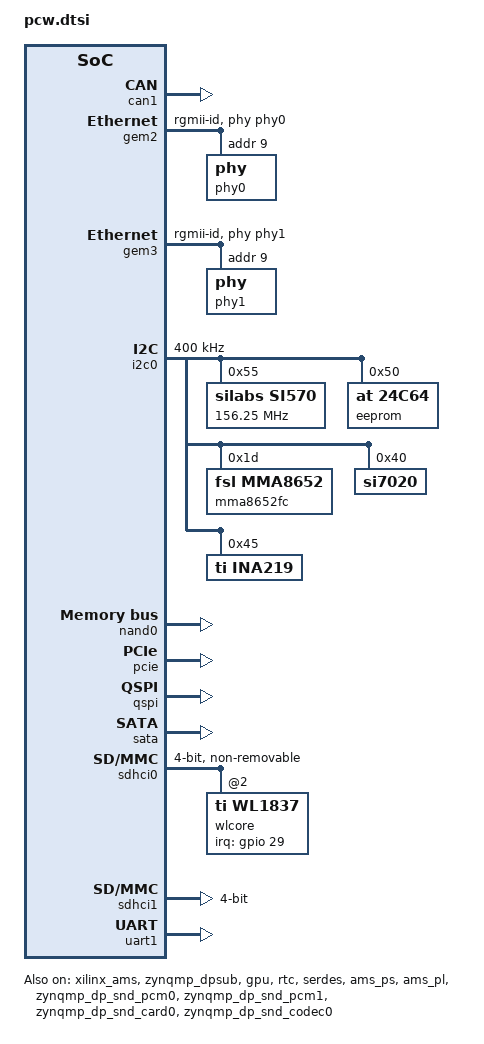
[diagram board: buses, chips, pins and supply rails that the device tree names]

/*
 * CAUTION: This file is automatically generated by Xilinx.
 * Version: XSCT 2018.3
 * Today is: Fri Feb  1 12:27:28 2019
 */


&gic {
	num_cpus = <2>;
	num_interrupts = <96>;
};
&lpd_dma_chan1 {
	status = "okay";
};
&lpd_dma_chan2 {
	status = "okay";
};
&lpd_dma_chan3 {
	status = "okay";
};
&lpd_dma_chan4 {
	status = "okay";
};
&lpd_dma_chan5 {
	status = "okay";
};
&lpd_dma_chan6 {
	status = "okay";
};
&lpd_dma_chan7 {
	status = "okay";
};
&lpd_dma_chan8 {
	status = "okay";
};
&xilinx_ams {
	status = "okay";
};
&perf_monitor_ocm {
	xlnx,enable-32bit-filter-id = <0x1>;
	xlnx,enable-advanced = <0x1>;
	xlnx,enable-event-count = <0x1>;
	xlnx,enable-event-log = <0x0>;
	xlnx,enable-profile = <0x0>;
	xlnx,enable-trace = <0x0>;
	xlnx,fifo-axis-depth = <0x20>;
	xlnx,fifo-axis-tdata-width = <0x38>;
	xlnx,fifo-axis-tid-width = <0x1>;
	xlnx,global-count-width = <0x20>;
	xlnx,have-sampled-metric-cnt = <0x1>;
	xlnx,metric-count-scale = <0x1>;
	xlnx,metrics-sample-count-width = <0x20>;
	xlnx,num-monitor-slots = <0x1>;
	xlnx,num-of-counters = <0x3>;
};
&can1 {
	status = "okay";
};
&zynqmp_dpsub {
	phy-names = "dp-phy0","dp-phy1";
	phys = <&lane3 5 0 2 135000000>,
		<&lane2 5 1 2 135000000>;
	status = "okay";
	xlnx,max-lanes = <2>;
};
&xlnx_dpdma {
	status = "okay";
};
&gem2 {
	status = "okay";
	phy-handle = <&phy0>;
	phy-mode = "rgmii-id";
    xlnx,ptp-enet-clock = <0x0>;
	phy-reset-gpio = <&gpio 10 1>;
	phy-reset-duration = <2>;
	phy-reset-active-low = <1>;
	local-mac-address = [00 0a 35 00 00 00];
	phy0: phy@9 {
			reg = <0x9>;
			ti,rx-internal-delay = <0x8>;
			ti,tx-internal-delay = <0xa>;
			ti,fifo-depth = <0x1>;
		};
};
&gem3 {
	status = "okay";
	phy-handle = <&phy1>;
	phy-mode = "rgmii-id";
	phy-reset-gpio = <&gpio 11 1>;
	phy-reset-duration = <2>;
	phy-reset-active-low = <1>;
	local-mac-address = [00 0a 35 00 00 01];
	phy1: phy@9 {
		reg = <0x9>;
		ti,rx-internal-delay = <0x8>;
		ti,tx-internal-delay = <0xa>;
		ti,fifo-depth = <0x1>;
		ti,rxctrl-strap-worka;
	};
};
&fpd_dma_chan1 {
	status = "okay";
};
&fpd_dma_chan2 {
	status = "okay";
};
&fpd_dma_chan3 {
	status = "okay";
};
&fpd_dma_chan4 {
	status = "okay";
};
&fpd_dma_chan5 {
	status = "okay";
};
&fpd_dma_chan6 {
	status = "okay";
};
&fpd_dma_chan7 {
	status = "okay";
};
&fpd_dma_chan8 {
	status = "okay";
};
&gpio {
	emio-gpio-width = <32>;
	gpio-mask-high = <0x0>;
	gpio-mask-low = <0x5600>;
	status = "okay";
};
&gpu {
	status = "okay";
};
&i2c0 {
	clock-frequency = <400000>;
	status = "okay";
	si570: clock-generator@55 {
		#clock-cells = <0>;
		compatible = "silabs,si570";
		reg = <0x55>;
		temperature-stability = <50>;
		factory-fout = <156250000>;
		clock-frequency = <156250000>;
	};
	
	eeprom@50 {
                compatible = "at,24c64";
                reg = <0x50>;
        };
	
	mma8652fc@1d {
		compatible = "fsl,mma8652";
		reg = <0x1d>;
	};	
	
	si7020@40 {
                compatible = "si7020";
                reg = <0x40>;
        };
	
	ina219@45 {
		compatible = "ti,ina219";
		reg = <0x45>;
		shunt-resistor = <2000>;
	};
};
&pinctrl0 {
	status = "okay";
};
&nand0 {
	status = "okay";
};
&pcie {
	status = "okay";
	xlnx,pcie-mode = "Root Port";
};
&qspi {
	is-dual = <0>;
	num-cs = <1>;
	spi-rx-bus-width = <4>;
	spi-tx-bus-width = <4>;
	status = "okay";
};
&rtc {
	status = "okay";
};
&sata {
	status = "okay";
};
&sdhci0 {
	clock-frequency = <50000000>;
	status = "okay";
	xlnx,mio_bank = <0x1>;
	
	non-removable;
	disable-wp;
	bus-width = <4>;
	
	//vmmc-supply = <&wlan_en>;
	max-frequency = <50000000>;
	
	cap-power-off-card;
	keep-power-in-suspend;
	
	#address-cells = <1>;
	#size-cells = <0>;
	wlcore: wlcore@2 {
		compatible = "ti,wl1837";
		reg = <2>;
		
		/* MIO 29 is IRQ now */
		interrupt-parent = <&gpio>;
		interrupts = <29 4>;
	};
};
&sdhci1 {
	clock-frequency = <100000000>;
	status = "okay";
	xlnx,mio_bank = <0x1>;
	no-1-8-v;
	disable-wp;
	bus-width = <4>;
};
&serdes {
	status = "okay";
};
&uart1 {
	device_type = "serial";
	port-number = <0>;
	status = "okay";
	u-boot,dm-pre-reloc ;
};
&pss_ref_clk {
	clock-frequency = <50000000>;
};
&fclk0 {
	status = "okay";
};
&ams_ps {
	status = "okay";
};
&ams_pl {
	status = "okay";
};
&zynqmp_dp_snd_pcm0 {
	status = "okay";
};
&zynqmp_dp_snd_pcm1 {
	status = "okay";
};
&zynqmp_dp_snd_card0 {
	status = "okay";
};
&zynqmp_dp_snd_codec0 {
	status = "okay";
};
